# ioam3358 register map
Registers are 32-bit, access not given, no defined reset value unless marked. A register's access mark holds for its fields unless they carry their own. Addresses are absolute; registers are grouped by the start of their names; [hi:lo] are bit positions; {n}, {i} and the like mark numbered series; 'fields as' and 'values as' point back to an identical list.

## EDMACC
0x49000000 EDMACC_PID
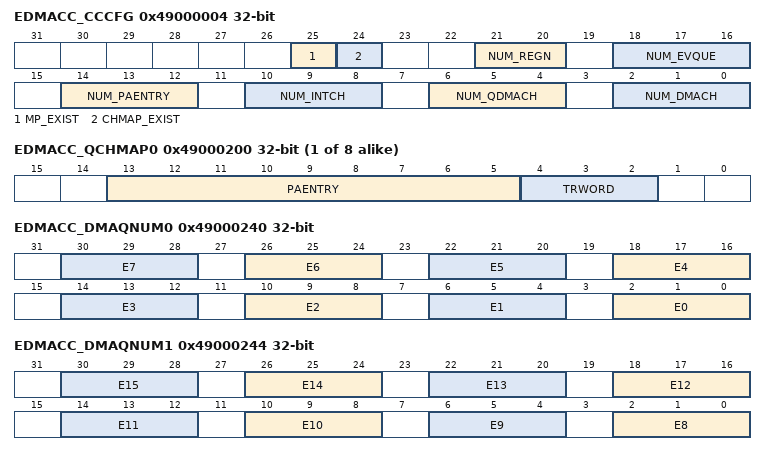
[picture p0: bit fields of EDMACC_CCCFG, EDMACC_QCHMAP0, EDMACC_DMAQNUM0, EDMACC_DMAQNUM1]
0x49000004 EDMACC_CCCFG
  [25] MP_EXIST, [24] CHMAP_EXIST, [21:20] NUM_REGN, [18:16] NUM_EVQUE, [14:12] NUM_PAENTRY, [10:8] NUM_INTCH, [6:4] NUM_QDMACH, [2:0] NUM_DMACH
{0x49000100+4i} EDMACC_DCHMAP{i} (i=0..63)
  [13:5] PAENTRY
{0x49000200+4i} EDMACC_QCHMAP{i} (i=0..7)
  [13:5] PAENTRY, [4:2] TRWORD
0x49000240 EDMACC_DMAQNUM0
  [4n+2:4n] E{n} (n=0..7)
0x49000244 EDMACC_DMAQNUM1
  [4n-30:4n-32] E{n} (n=8..15)
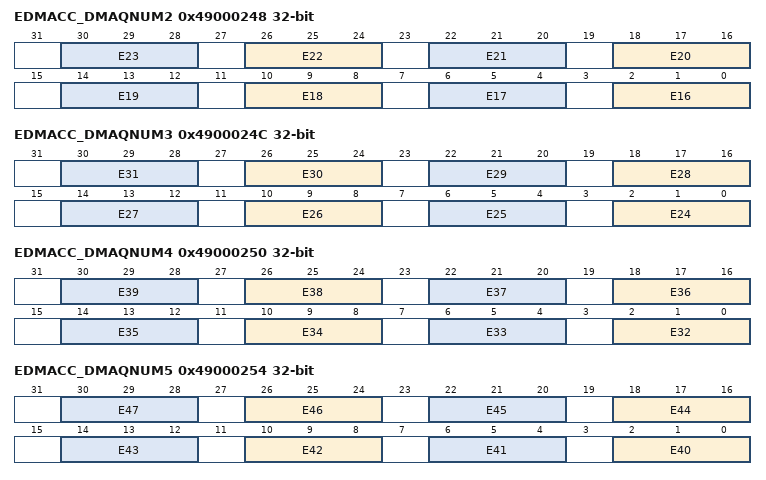
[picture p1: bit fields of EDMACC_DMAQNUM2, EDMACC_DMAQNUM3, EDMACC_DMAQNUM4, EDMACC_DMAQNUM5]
0x49000248 EDMACC_DMAQNUM2
  [4n-62:4n-64] E{n} (n=16..23)
0x4900024C EDMACC_DMAQNUM3
  [4n-94:4n-96] E{n} (n=24..31)
0x49000250 EDMACC_DMAQNUM4
  [4n-126:4n-128] E{n} (n=32..39)
0x49000254 EDMACC_DMAQNUM5
  [4n-158:4n-160] E{n} (n=40..47)
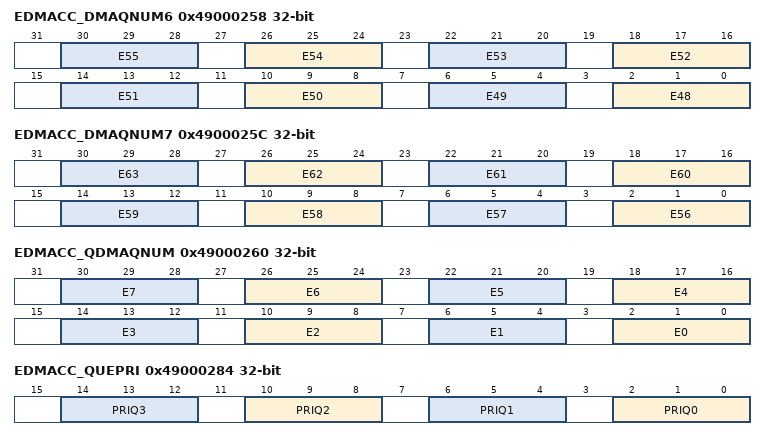
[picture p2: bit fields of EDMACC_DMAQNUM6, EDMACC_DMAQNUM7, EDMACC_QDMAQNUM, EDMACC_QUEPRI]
0x49000258 EDMACC_DMAQNUM6
  [4n-190:4n-192] E{n} (n=48..55)
0x4900025C EDMACC_DMAQNUM7
  [4n-222:4n-224] E{n} (n=56..63)
0x49000260 EDMACC_QDMAQNUM
  [4n+2:4n] E{n} (n=0..7)
0x49000284 EDMACC_QUEPRI
  [4n+2:4n] PRIQ{n} (n=0..3)
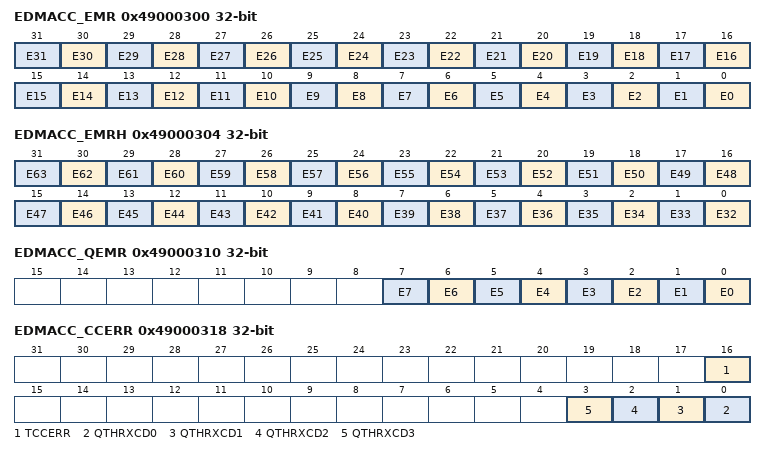
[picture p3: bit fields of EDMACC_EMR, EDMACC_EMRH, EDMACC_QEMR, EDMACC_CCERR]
0x49000300 EDMACC_EMR
  [n] E{n} (n=0..31)
0x49000304 EDMACC_EMRH
  [n-32] E{n} (n=32..63)
0x49000308 EDMACC_EMCR
0x4900030C EDMACC_EMCRH
0x49000310 EDMACC_QEMR
  [n] E{n} (n=0..7)
0x49000314 EDMACC_QEMCR
0x49000318 EDMACC_CCERR
  [16] TCCERR, [n] QTHRXCD{n} (n=0..3)
0x4900031C EDMACC_CCERRCLR
0x49000320 EDMACC_EEVAL
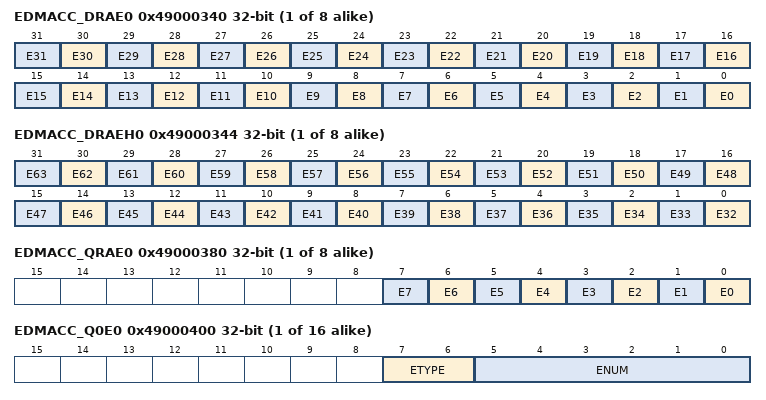
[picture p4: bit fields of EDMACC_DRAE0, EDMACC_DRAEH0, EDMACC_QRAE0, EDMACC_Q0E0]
{0x49000340+8i} EDMACC_DRAE{i} (i=0..7)
  [n] E{n} (n=0..31)
{0x49000344+8i} EDMACC_DRAEH{i} (i=0..7)
  [n-32] E{n} (n=32..63)
{0x49000380+4i} EDMACC_QRAE{i} (i=0..7)
  [n] E{n} (n=0..7)
{0x49000400+4i} EDMACC_Q0E{i} (i=0..15)
  [7:6] ETYPE, [5:0] ENUM
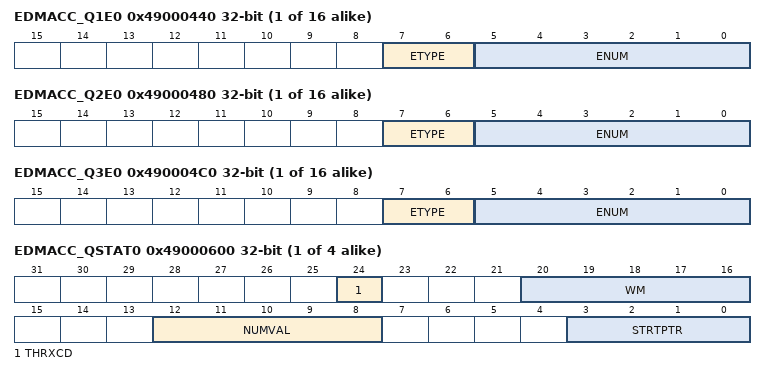
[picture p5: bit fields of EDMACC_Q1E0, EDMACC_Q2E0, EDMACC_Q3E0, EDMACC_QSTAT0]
{0x49000440+4i} EDMACC_Q1E{i} (i=0..15)
  [7:6] ETYPE, [5:0] ENUM
{0x49000480+4i} EDMACC_Q2E{i} (i=0..15)
  [7:6] ETYPE, [5:0] ENUM
{0x490004C0+4i} EDMACC_Q3E{i} (i=0..15)
  [7:6] ETYPE, [5:0] ENUM
{0x49000600+4i} EDMACC_QSTAT{i} (i=0..3)
  [24] THRXCD, [20:16] WM, [12:8] NUMVAL, [3:0] STRTPTR
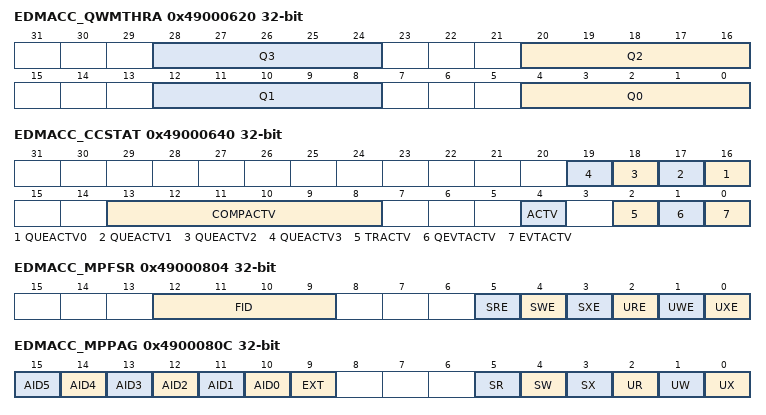
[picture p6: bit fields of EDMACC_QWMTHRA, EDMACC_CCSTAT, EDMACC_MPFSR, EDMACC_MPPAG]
0x49000620 EDMACC_QWMTHRA
  [8n+4:8n] Q{n} (n=0..3)
0x49000640 EDMACC_CCSTAT
  [n+16] QUEACTV{n} (n=0..3), [13:8] COMPACTV, [4] ACTV, [2] TRACTV, [1] QEVTACTV, [0] EVTACTV
0x49000800 EDMACC_MPFAR
0x49000804 EDMACC_MPFSR
  [12:9] FID, [5] SRE, [4] SWE, [3] SXE, [2] URE, [1] UWE, [0] UXE
0x49000808 EDMACC_MPFCR
0x4900080C EDMACC_MPPAG
  [n+10] AID{n} (n=0..5), [9] EXT, [5] SR, [4] SW, [3] SX, [2] UR, [1] UW, [0] UX
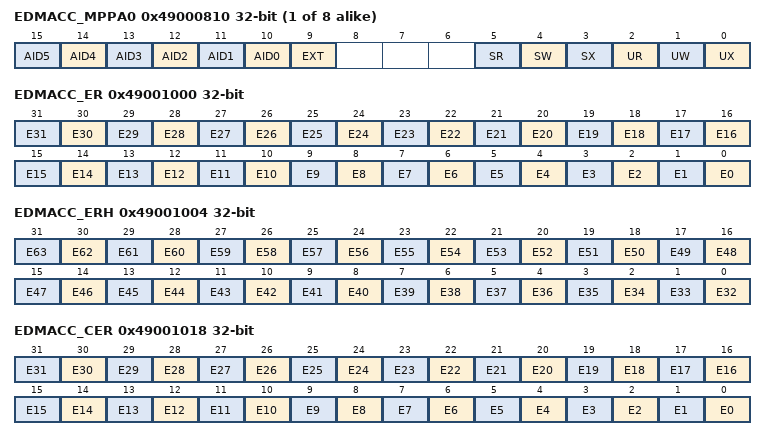
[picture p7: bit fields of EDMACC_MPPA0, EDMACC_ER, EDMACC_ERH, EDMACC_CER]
{0x49000810+4i} EDMACC_MPPA{i} (i=0..7)
  fields as EDMACC_MPPAG
0x49001000 EDMACC_ER
  [n] E{n} (n=0..31)
0x49001004 EDMACC_ERH
  [n-32] E{n} (n=32..63)
0x49001008 EDMACC_ECR
0x4900100C EDMACC_ECRH
0x49001010 EDMACC_ESR
0x49001014 EDMACC_ESRH
0x49001018 EDMACC_CER
  [n] E{n} (n=0..31)
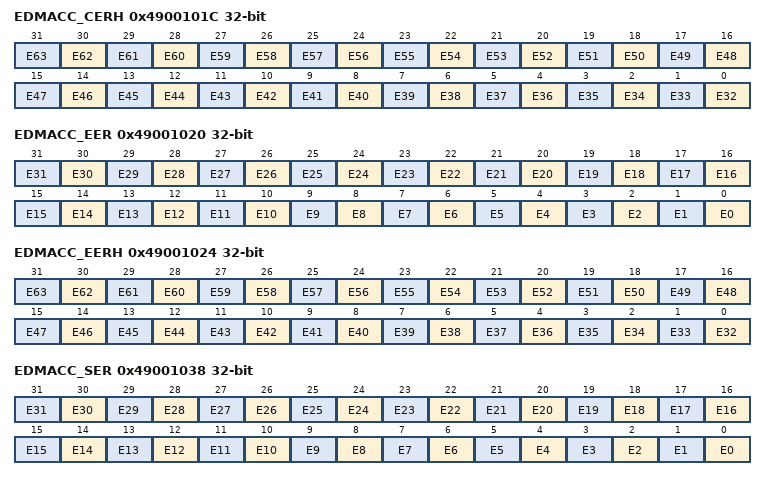
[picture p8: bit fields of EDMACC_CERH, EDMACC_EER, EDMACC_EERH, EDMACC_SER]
0x4900101C EDMACC_CERH
  [n-32] E{n} (n=32..63)
0x49001020 EDMACC_EER
  [n] E{n} (n=0..31)
0x49001024 EDMACC_EERH
  [n-32] E{n} (n=32..63)
0x49001028 EDMACC_EECR
0x4900102C EDMACC_EECRH
0x49001030 EDMACC_EESR
0x49001034 EDMACC_EESRH
0x49001038 EDMACC_SER
  [n] E{n} (n=0..31)
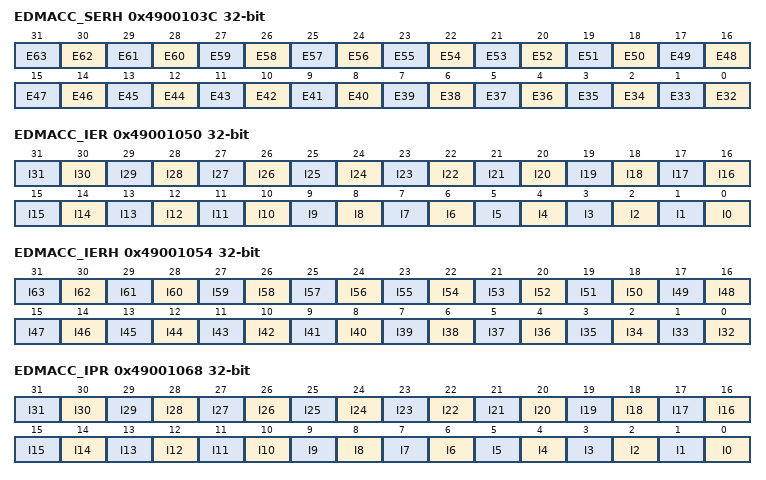
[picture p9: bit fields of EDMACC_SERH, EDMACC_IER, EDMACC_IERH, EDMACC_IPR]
0x4900103C EDMACC_SERH
  [n-32] E{n} (n=32..63)
0x49001040 EDMACC_SECR
0x49001044 EDMACC_SECRH
0x49001050 EDMACC_IER
  [n] I{n} (n=0..31)
0x49001054 EDMACC_IERH
  [n-32] I{n} (n=32..63)
0x49001058 EDMACC_IECR
0x4900105C EDMACC_IECRH
0x49001060 EDMACC_IESR
0x49001064 EDMACC_IESRH
0x49001068 EDMACC_IPR
  [n] I{n} (n=0..31)
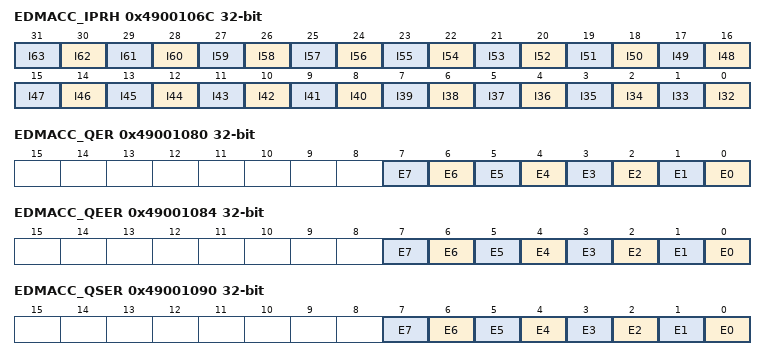
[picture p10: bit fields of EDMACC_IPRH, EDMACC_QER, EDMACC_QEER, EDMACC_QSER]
0x4900106C EDMACC_IPRH
  [n-32] I{n} (n=32..63)
0x49001070 EDMACC_ICR
0x49001074 EDMACC_ICRH
0x49001078 EDMACC_IEVAL
0x49001080 EDMACC_QER
  [n] E{n} (n=0..7)
0x49001084 EDMACC_QEER
  [n] E{n} (n=0..7)
0x49001088 EDMACC_QEECR
0x4900108C EDMACC_QEESR
0x49001090 EDMACC_QSER
  [n] E{n} (n=0..7)
0x49001094 EDMACC_QSECR
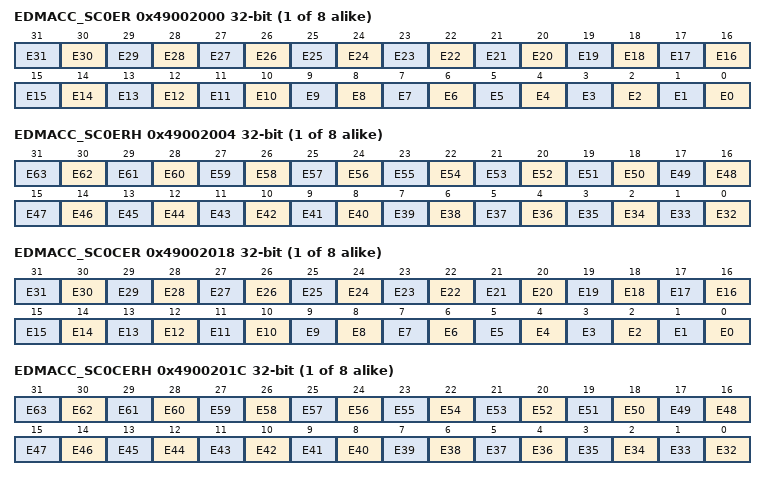
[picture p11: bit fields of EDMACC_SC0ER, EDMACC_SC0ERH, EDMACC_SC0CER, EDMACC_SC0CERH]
{0x49002000+0x200*i} EDMACC_SC{i}ER (i=0..7)
  [n] E{n} (n=0..31)
{0x49002004+0x200*i} EDMACC_SC{i}ERH (i=0..7)
  [n-32] E{n} (n=32..63)
{0x49002008+0x200*i} EDMACC_SC{i}ECR (i=0..7)
{0x4900200C+0x200*i} EDMACC_SC{i}ECRH (i=0..7)
{0x49002010+0x200*i} EDMACC_SC{i}ESR (i=0..7)
{0x49002014+0x200*i} EDMACC_SC{i}ESRH (i=0..7)
{0x49002018+0x200*i} EDMACC_SC{i}CER (i=0..7)
  [n] E{n} (n=0..31)
{0x4900201C+0x200*i} EDMACC_SC{i}CERH (i=0..7)
  [n-32] E{n} (n=32..63)
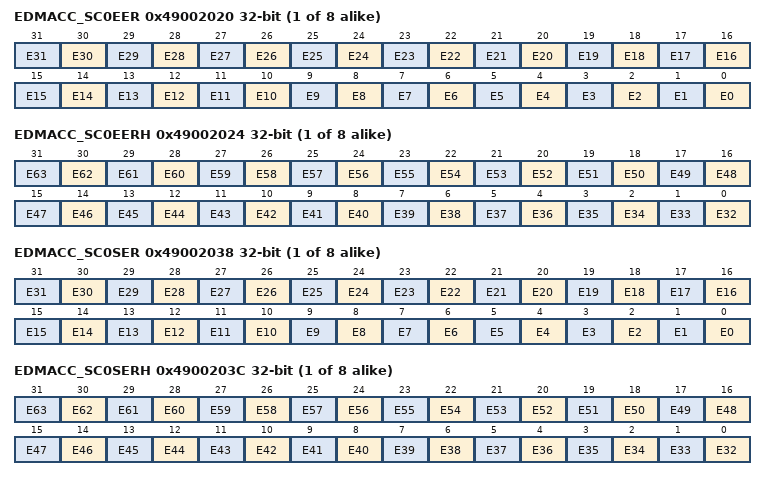
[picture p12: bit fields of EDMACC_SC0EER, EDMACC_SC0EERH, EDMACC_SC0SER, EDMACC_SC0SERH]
{0x49002020+0x200*i} EDMACC_SC{i}EER (i=0..7)
  [n] E{n} (n=0..31)
{0x49002024+0x200*i} EDMACC_SC{i}EERH (i=0..7)
  [n-32] E{n} (n=32..63)
{0x49002028+0x200*i} EDMACC_SC{i}EECR (i=0..7)
{0x4900202C+0x200*i} EDMACC_SC{i}EECRH (i=0..7)
{0x49002030+0x200*i} EDMACC_SC{i}EESR (i=0..7)
{0x49002034+0x200*i} EDMACC_SC{i}EESRH (i=0..7)
{0x49002038+0x200*i} EDMACC_SC{i}SER (i=0..7)
  [n] E{n} (n=0..31)
{0x4900203C+0x200*i} EDMACC_SC{i}SERH (i=0..7)
  [n-32] E{n} (n=32..63)
{0x49002040+0x200*i} EDMACC_SC{i}SECR (i=0..7)
{0x49002044+0x200*i} EDMACC_SC{i}SECRH (i=0..7)
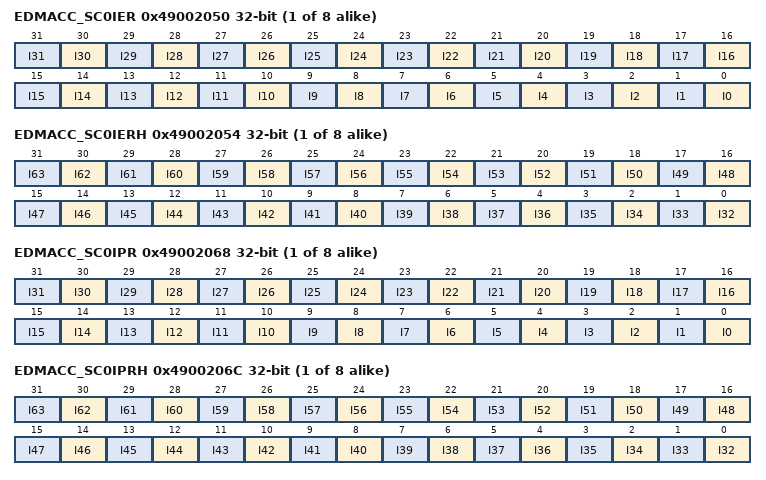
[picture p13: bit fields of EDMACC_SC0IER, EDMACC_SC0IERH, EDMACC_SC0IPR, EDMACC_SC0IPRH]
{0x49002050+0x200*i} EDMACC_SC{i}IER (i=0..7)
  [n] I{n} (n=0..31)
{0x49002054+0x200*i} EDMACC_SC{i}IERH (i=0..7)
  [n-32] I{n} (n=32..63)
{0x49002058+0x200*i} EDMACC_SC{i}IECR (i=0..7)
{0x4900205C+0x200*i} EDMACC_SC{i}IECRH (i=0..7)
{0x49002060+0x200*i} EDMACC_SC{i}IESR (i=0..7)
{0x49002064+0x200*i} EDMACC_SC{i}IESRH (i=0..7)
{0x49002068+0x200*i} EDMACC_SC{i}IPR (i=0..7)
  [n] I{n} (n=0..31)
{0x4900206C+0x200*i} EDMACC_SC{i}IPRH (i=0..7)
  [n-32] I{n} (n=32..63)
{0x49002070+0x200*i} EDMACC_SC{i}ICR (i=0..7)
{0x49002074+0x200*i} EDMACC_SC{i}ICRH (i=0..7)
{0x49002078+0x200*i} EDMACC_SC{i}IEVAL (i=0..7)
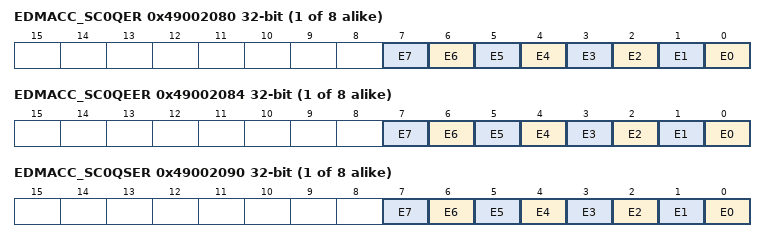
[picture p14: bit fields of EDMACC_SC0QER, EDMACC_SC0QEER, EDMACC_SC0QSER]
{0x49002080+0x200*i} EDMACC_SC{i}QER (i=0..7)
  [n] E{n} (n=0..7)
{0x49002084+0x200*i} EDMACC_SC{i}QEER (i=0..7)
  [n] E{n} (n=0..7)
{0x49002088+0x200*i} EDMACC_SC{i}QEECR (i=0..7)
{0x4900208C+0x200*i} EDMACC_SC{i}QEESR (i=0..7)
{0x49002090+0x200*i} EDMACC_SC{i}QSER (i=0..7)
  [n] E{n} (n=0..7)
{0x49002094+0x200*i} EDMACC_SC{i}QSECR (i=0..7)
0x49004000 EDMACC_PaRAM_BA
